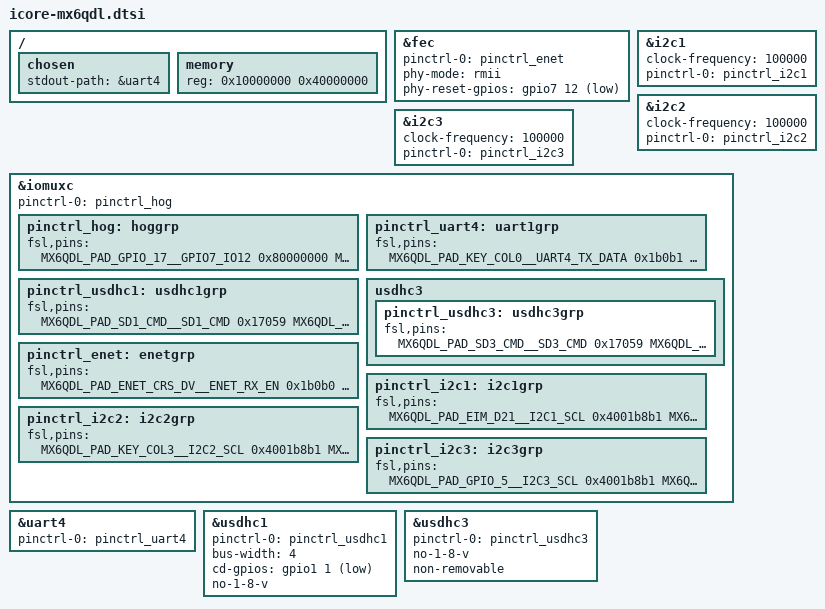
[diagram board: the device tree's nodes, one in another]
// SPDX-License-Identifier: GPL-2.0+
//
// Copyright 2012 Freescale Semiconductor, Inc.
// Copyright 2011 Linaro Ltd.
// Copyright 2017 NXP.

#include <dt-bindings/clock/imx6qdl-clock.h>

#include <dt-bindings/gpio/gpio.h>
#include <dt-bindings/input/input.h>
#include "icoremx6dl-pinfunc.h"

/ {

	chosen {
		stdout-path = &uart4;
	};

	memory: memory {
		reg = <0x10000000 0x40000000>;
	};
};

&fec {
	pinctrl-names = "default";
	pinctrl-0 = <&pinctrl_enet>;
	phy-mode = "rmii";
	phy-reset-gpios = <&gpio7 12 GPIO_ACTIVE_LOW>;
	status = "okay";
};

&i2c1 {
	status = "okay";
	clock-frequency = <100000>;
	pinctrl-names = "default";
	pinctrl-0 = <&pinctrl_i2c1>;
};

&i2c2 {
	status = "okay";
	clock-frequency = <100000>;
	pinctrl-names = "default";
	pinctrl-0 = <&pinctrl_i2c2>;
};

&i2c3 {
	status = "okay";
	clock-frequency = <100000>;
	pinctrl-names = "default";
	pinctrl-0 = <&pinctrl_i2c3>;
};

&iomuxc {
	pinctrl-names = "default";
	pinctrl-0 = <&pinctrl_hog>;
  
  pinctrl_hog: hoggrp {
    fsl,pins = <
      MX6QDL_PAD_GPIO_17__GPIO7_IO12 0x80000000
      MX6QDL_PAD_GPIO_1__GPIO1_IO01  0x80000000
      MX6QDL_PAD_EIM_BCLK__GPIO6_IO31 0x80000000 // EDIMM_VERSION
    >;
  };
  
  pinctrl_uart4: uart1grp {
    fsl,pins = <
      MX6QDL_PAD_KEY_COL0__UART4_TX_DATA	0x1b0b1
      MX6QDL_PAD_KEY_ROW0__UART4_RX_DATA	0x1b0b1
    >;
  };
  
  pinctrl_usdhc1: usdhc1grp {
    fsl,pins = <
      MX6QDL_PAD_SD1_CMD__SD1_CMD		0x17059
      MX6QDL_PAD_SD1_CLK__SD1_CLK		0x10059
      MX6QDL_PAD_SD1_DAT0__SD1_DATA0		0x17059
      MX6QDL_PAD_SD1_DAT1__SD1_DATA1		0x17059
      MX6QDL_PAD_SD1_DAT2__SD1_DATA2		0x17059
      MX6QDL_PAD_SD1_DAT3__SD1_DATA3		0x17059
    >;
  };

	usdhc3 {
		pinctrl_usdhc3: usdhc3grp {
			fsl,pins = <
				MX6QDL_PAD_SD3_CMD__SD3_CMD    0x17059
				MX6QDL_PAD_SD3_CLK__SD3_CLK    0x10059
				MX6QDL_PAD_SD3_DAT0__SD3_DATA0 0x17059
				MX6QDL_PAD_SD3_DAT1__SD3_DATA1 0x17059
				MX6QDL_PAD_SD3_DAT2__SD3_DATA2 0x17059
				MX6QDL_PAD_SD3_DAT3__SD3_DATA3 0x17059
				MX6QDL_PAD_SD3_DAT4__SD3_DATA4 0x17059
				MX6QDL_PAD_SD3_DAT5__SD3_DATA5 0x17059
				MX6QDL_PAD_SD3_DAT6__SD3_DATA6 0x17059
				MX6QDL_PAD_SD3_DAT7__SD3_DATA7 0x17059
			>;
		};
  };

		pinctrl_enet: enetgrp {
			fsl,pins = <
				MX6QDL_PAD_ENET_CRS_DV__ENET_RX_EN 	0x1b0b0
				MX6QDL_PAD_ENET_TX_EN__ENET_TX_EN	0x1b0b0
				MX6QDL_PAD_ENET_RXD1__ENET_RX_DATA1	0x1b0b0
				MX6QDL_PAD_ENET_RXD0__ENET_RX_DATA0	0x1b0b0
				MX6QDL_PAD_ENET_TXD1__ENET_TX_DATA1	0x1b0b0
				MX6QDL_PAD_ENET_TXD0__ENET_TX_DATA0	0x1b0b0
        MX6QDL_PAD_ENET_MDC__ENET_MDC	   	0x1b0b0
				MX6QDL_PAD_ENET_MDIO__ENET_MDIO		0x1b0b0
				MX6QDL_PAD_ENET_REF_CLK__GPIO1_IO23	0x1b0b0
				MX6QDL_PAD_GPIO_17__GPIO7_IO12		0x1b0b0
				MX6QDL_PAD_EIM_BCLK__GPIO6_IO31		0x1b0b0 /* EDIMM 1.5 or 1.0 GPIO signal */
				MX6QDL_PAD_GPIO_16__ENET_REF_CLK_SION 0x4001b0a8
			>;
		};

		pinctrl_i2c1: i2c1grp {
			fsl,pins = <
        MX6QDL_PAD_EIM_D21__I2C1_SCL 0x4001b8b1
				MX6QDL_PAD_EIM_D28__I2C1_SDA 0x4001b8b1
			>;
		};

		pinctrl_i2c2: i2c2grp {
			fsl,pins = <
				MX6QDL_PAD_KEY_COL3__I2C2_SCL 0x4001b8b1
				MX6QDL_PAD_KEY_ROW3__I2C2_SDA 0x4001b8b1
			>;
		};


		pinctrl_i2c3: i2c3grp {
			fsl,pins = <
				MX6QDL_PAD_GPIO_5__I2C3_SCL  0x4001b8b1
				MX6QDL_PAD_EIM_D18__I2C3_SDA 0x4001b8b1
				MX6QDL_PAD_GPIO_0__CCM_CLKO1	0x130b0
			>;
		};

};

&uart4 {
	pinctrl-names = "default";
	pinctrl-0 = <&pinctrl_uart4>;
	status = "okay";
};

&usdhc1 {
	pinctrl-names = "default";
	pinctrl-0 = <&pinctrl_usdhc1>;
	bus-width = <4>;
	cd-gpios = <&gpio1 1 GPIO_ACTIVE_LOW>;
	no-1-8-v;
	status = "okay";
};

&usdhc3 {
	pinctrl-names = "default";
	pinctrl-0 = <&pinctrl_usdhc3>;
	no-1-8-v;
	non-removable;
	status = "okay";
};
